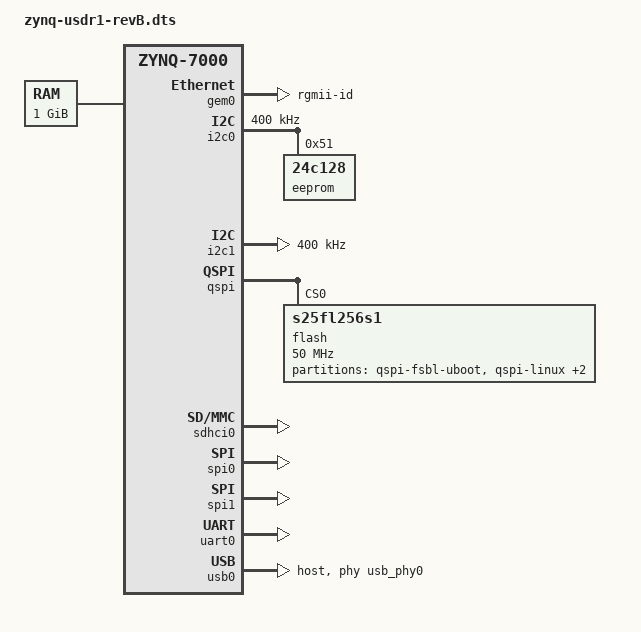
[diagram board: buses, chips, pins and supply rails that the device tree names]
/*
 * CAUTION: This file is automatically generated by Xilinx.
 * Version:  
 * Today is: Tue Jan 29 15:43:04 2019
 */


/dts-v1/;
/include/ "zynq-7000.dtsi"

/ {
	chosen {
		bootargs = "earlycon";
		stdout-path = "serial0:115200n8";
	};
	aliases {
		ethernet0 = &gem0;
		serial0 = &uart0;
		spi0 = &qspi;
		spi1 = &spi0;
		spi2 = &spi1;
	};
	memory {
		device_type = "memory";
		reg = <0x0 0x40000000>;
	};
	
	usb_phy0: phy0@e0002000 {
		compatible = "usb-nop-xceiv";
		#phy-cells = <0>;
		reg = <0xe0002000 0x1000>;
		view-port = <0x0170>;
		drv-vbus;
   };
};

/ {
	cpus {
		cpu@0 {
			operating-points = <666666 1000000 333333 1000000>;
		};
	};
};
&gem0 {
	enet-reset = <&gpio0 49 0>;
	phy-mode = "rgmii-id";
	status = "okay";
	xlnx,ptp-enet-clock = <0x69f6bcb>;
};
&gpio0 {
	emio-gpio-width = <64>;
	gpio-mask-high = <0x0>;
	gpio-mask-low = <0x5600>;
};
&i2c0 {
	clock-frequency = <400000>;
	status = "okay";
	
	 eeprom@51 {
		compatible = "24c128";
		reg = <0x51>;
	};
};
&i2c1 {
	clock-frequency = <400000>;
	status = "okay";
};
&intc {
	num_cpus = <2>;
	num_interrupts = <96>;
};
&qspi {
	is-dual = <0>;
	num-cs = <1>;
	spi-rx-bus-width = <4>;
	spi-tx-bus-width = <4>;
	status = "okay";
	flash@0 {
		compatible = "s25fl256s1";
		reg = <0x0>;
		spi-max-frequency = <50000000>;
		#address-cells = <1>;
		#size-cells = <1>;
		partition@qspi-fsbl-uboot {
				label = "qspi-fsbl-uboot";
				reg = <0x0 0x500000>;
		};
		partition@qspi-linux {
				label = "qspi-linux";
				reg = <0x100000 0x500000>;
		};
		partition@qspi-device-tree {
				label = "qspi-device-tree";
				reg = <0x600000 0x20000>;
		};
		partition@qspi-rootfs {
				label = "qspi-rootfs";
				reg = <0x620000 0x15E0000>;
		};
	};
};
&sdhci0 {
	status = "okay";
	xlnx,has-cd = <0x1>;
	xlnx,has-power = <0x0>;
	xlnx,has-wp = <0x0>;
};
&spi0 {
	is-decoded-cs = <0>;
	num-cs = <3>;
	status = "okay";
};
&spi1 {
	is-decoded-cs = <0>;
	num-cs = <3>;
	status = "okay";
};
&uart0 {
	device_type = "serial";
	port-number = <0>;
	status = "okay";
};
&usb0 {
	phy_type = "ulpi";
	usb-phy = <&usb_phy0>;
	dr_mode = "host";
	status = "okay";
};
&clkc {
	fclk-enable = <0x0>;
	ps-clk-frequency = <33333333>;
};

